# cslr_anactrl register map
Vendor: Texas Instruments
Peripheral module from a debugger description file (folder C5545).
Address unit: 16 bits
Registers are 16-bit, access not given, reset 0x0 unless marked. A register's access mark holds for its fields unless they carry their own. Offsets are as the file gives them; lines under a group give offsets from that group; [hi:lo] are bit positions; {n}, {i} and the like mark numbered series; 'fields as' and 'values as' point back to an identical list; <NAME> marks a mode.

## ANACTRL — SAR registers & USB LDO Control
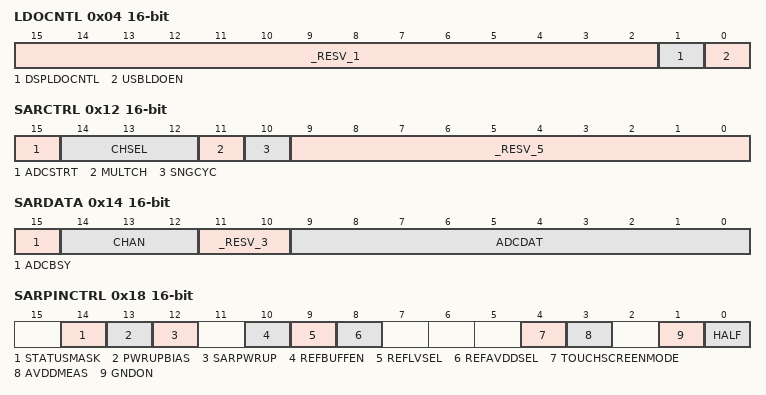
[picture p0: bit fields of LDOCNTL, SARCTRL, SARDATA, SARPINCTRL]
0x04 LDOCNTL — USB LDO enable register
  [15:2] _RESV_1 — (access N)
  [1] DSPLDOCNTL rw — Used to select the DSP LDO voltage
    0=1.3V (DSP LDO Output Voltage is regulated to 1.3 V.); 1=1.05V (DSP LDO Output Voltage is regulated to 1.05 V.)
  [0] USBLDOEN rw — Used to enable the USB LDO
    0=disabled (USB LDO is disabled); 1=enabled (USB LDO is enabled)
0x12 SARCTRL — SAR Control Register
  [15] ADCSTRT rw — ADC start
    0=CLEAR (No Conversion); 1=SET (Start conversion cycle)
  [14:12] CHSEL rw — Channel Selection
    {v}=AIN{v} (Analog Input Ch{v} selcted) (v=0..5); 6=RES0; 7=RES1
  [11] MULTCH rw — MultiChannel mode
    0=CLEAR (No discharge of array); 1=SET (Discharge array after switching to new channel and performing a new conversion.)
  [10] SNGCYC rw — single cycle mode
    0=CLEAR (continously perform conversions as long as SDC Start is set); 1=SET (Perform 1 conversion and stop. ADC start must be cleared and then set high to perform another conversion)
  [9:0] _RESV_5 — (access N)
0x14 SARDATA
  [15] ADCBSY ro — ADC busy status
    0=CLEAR (ADC data available); 1=SET (ADC Busy)
  [14:12] CHAN ro — Channel Selection
    {v}=AIN{v} (Analog Input Ch{v} was selcted) (v=0..5); 6=RES0; 7=RES1
  [11:10] _RESV_3 — Reseverd (access N)
  [9:0] ADCDAT ro — Converter Data
0x16 SARCLKCTRL — SAR Clock Control Register
  [6:0] ADCCLKDIV rw — specifies the divider rate of the system clock: Fsar_clock = (Fsystem_clock)/(ADCCLKDIV[14:0]+1)
0x18 SARPINCTRL — SAR Pin Control Register
  [14] STATUSMASK rw — Asserting this bit causes the channel selected and ADC busy bits from being added into the memory.
    0=CLEAR (The SARDATA register includes the status info in bits 12-15); 1=SET (The SARDATA register bits 12-15 are always 0000)
  [13] PWRUPBIAS rw — Enables the current bias circuit which is needed for the SAR to perform A/D conversion
    0=CLEAR (Powered Down (low power setting)); 1=SET (Powered up. Required for A/D)
  [12] SARPWRUP rw — 0:SAR_analog powered down, 1:SAR_analog powered up
    0=CLEAR (SAR analog Powered down); 1=SET (SAR analog Power present)
  [10] REFBUFFEN rw — Reference buffer enable
    0=CLEAR (Ref Buffer disabled (low power setting)); 1=SET (Ref Buffer enabled. Required when using bandgap generated Vref)
  [9] REFLVSEL rw — Bandgap based reference voltage value select
    0=CLEAR (Bandgap based ref voltage set to .8V); 1=SET (BG based ref voltage set to 1V)
  [8] REFAVDDSEL rw — ADC Reference voltage select
    0=CLEAR (BG based ref voltage is used for ADC ref voltage); 1=SET (Ref voltage is set to Analog Voltage)
  [4] TOUCHSCREENMODE rw — Enables Touchscreen mode
    0=CLEAR (Touchscreen mode disabled); 1=SET (Touchscreen mode enabled)
  [3] AVDDMEAS rw — enable measurement of internal analog voltage
    0=CLEAR (analog voltage not connected to ch 3 ADC); 1=SET (analog voltage connected to CH 3 ADC)
  [1] GNDON rw — SAR CH0 is grounded and resistor divider network on CH1
    0=CLEAR (SAR Ana CH0 not grounded); 1=SET (SAR Ana CH0 grounded and resistor divider on Ch1)
  [0] HALF rw — ADC analog input divided by 2 before conversion
    0=CLEAR (A/D conversion based on Vin); 1=SET (A/D conversion based on Vin/2)
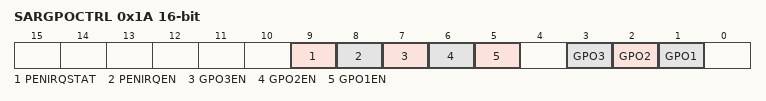
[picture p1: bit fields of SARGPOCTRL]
0x1A SARGPOCTRL — SAR GPO Control register
  [9] PENIRQSTAT ro — Pen Interrupt Status
    0=CLEAR (No Pen input detected); 1=SET (Pen input detected)
  [8] PENIRQEN rw — Pen Interrupt request Enable
    0=CLEAR (Disable Pen interrupt); 1=SET (Enable Pen interrupt (SAR interrupt signal))
  [7] GPO3EN rw — Enable general purpose output on GPO3
    0=CLEAR (GPAIN3 output driver disabled); 1=SET (GPAIN3 used as output)
  [6] GPO2EN rw — Enable general purpose output on GPO2
    0=CLEAR (GPAIN2 output driver disabled); 1=SET (GPAIN2 used as output)
  [5] GPO1EN rw — Enable general purpose output on GPO1
    0=CLEAR (GPAIN1 output driver disabled); 1=SET (GPAIN1 used as output)
  [3] GPO3 rw — GP3 grounded or driven high
    0=CLEAR (GPAIN3 grounded); 1=SET (GPAIN3 driven High)
  [2] GPO2 rw — GP2 grounded or driven high
    0=CLEAR (GPAIN2 grounded); 1=SET (GPAIN2 driven High)
  [1] GPO1 rw — GP1 grounded or driven high
    0=CLEAR (GPAIN1 grounded); 1=SET (GPAIN1 driven High)
